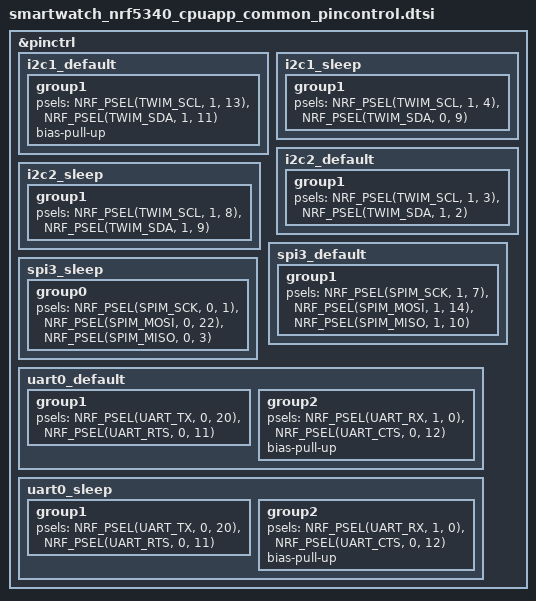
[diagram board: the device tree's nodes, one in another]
&pinctrl {

	// I2C
	i2c1_default: i2c1_default {
		group1 {
				psels = <NRF_PSEL(TWIM_SCL, 1, 13)>,
						<NRF_PSEL(TWIM_SDA, 1, 11)>;
						bias-pull-up;
		};
	};
	i2c1_sleep: i2c1_sleep {
			group1 {
					psels = <NRF_PSEL(TWIM_SCL, 1, 4)>,
							<NRF_PSEL(TWIM_SDA, 0, 9)>;
			};
	};

	i2c2_default: i2c2_default {
		group1 {
				psels = <NRF_PSEL(TWIM_SCL, 1, 3)>,
						<NRF_PSEL(TWIM_SDA, 1, 2)>;
		};
	};
	i2c2_sleep: i2c2_sleep {
			group1 {
					psels = <NRF_PSEL(TWIM_SCL, 1, 8)>,
							<NRF_PSEL(TWIM_SDA, 1, 9)>;
			};
	};


	// SPI
	spi3_default: spi3_default {
		group1 {
				psels = <NRF_PSEL(SPIM_SCK, 1, 7)>,
						<NRF_PSEL(SPIM_MOSI, 1, 14)>,
						<NRF_PSEL(SPIM_MISO, 1, 10)>;
			};
	};
	spi3_sleep: spi3_sleep {
			group0 {
					psels = <NRF_PSEL(SPIM_SCK, 0, 1)>,
							<NRF_PSEL(SPIM_MOSI, 0, 22)>,
							<NRF_PSEL(SPIM_MISO, 0, 3)>;
			};
	};



	
	// UART
	uart0_default: uart0_default {
		group1 {
			psels = <NRF_PSEL(UART_TX, 0, 20)>,
			<NRF_PSEL(UART_RTS, 0, 11)>;
		};
		group2 {
			psels = <NRF_PSEL(UART_RX, 1, 0)>,
				<NRF_PSEL(UART_CTS, 0, 12)>;
			bias-pull-up;
		};
	};

	uart0_sleep: uart0_sleep {
		group1 {
			psels = <NRF_PSEL(UART_TX, 0, 20)>,
			<NRF_PSEL(UART_RTS, 0, 11)>;
		};
		group2 {
			psels = <NRF_PSEL(UART_RX, 1, 0)>,
				<NRF_PSEL(UART_CTS, 0, 12)>;
			bias-pull-up;
		};
	};	
	
};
